VERSION ""

NS_ :

BS_:

BU_: BMS OBC VCU HCM MCU
VAL_TABLE_ Busoff_state 1 "Bus Off" 0 "Normal" ;
VAL_TABLE_ contactor_fault 2 "Open the Way" 1 "Adhesive" 0 "Normal" ;
VAL_TABLE_ LV_power_supply_failure 3 "Sampling Fault" 2 "Overpressure" 1 "Underpressure" 0 "Normal" ;
VAL_TABLE_ HCM_precharge_state 5 "Normal Drive" 4 "Precharge and Locking" 3 "Precharge Fault" 2 "Precharge Completed" 1 "Precharge Process" 0 "Open Circuit" ;
VAL_TABLE_ Charging_wakeup_state 1 "Activation" 0 "Unactivated" ;
VAL_TABLE_ Output_overpressure 1 "Fault" 0 "Normal" ;
VAL_TABLE_ Input_under_pressure 1 "Fault" 0 "Normal" ;
VAL_TABLE_ Input_underpressure 1 "Fault" 0 "Normal" ;
VAL_TABLE_ Enter_overpressure 1 "Fault" 0 "Normal" ;
VAL_TABLE_ Overtemperature_failure 1 "Fault" 0 "Normal" ;
VAL_TABLE_ Self_inspection_fault 1 "Fault" 0 "Normal" ;
VAL_TABLE_ Output_overflow 1 "Fault" 0 "Normal" ;
VAL_TABLE_ Communication_failure 1 "Fault" 0 "Normal" ;
VAL_TABLE_ DCDC_running_state 5 "Fault" 6 "Shutdown" 3 "Enabled" 2 "High Pressure on Top" 1 "Self Pass" 0 "Initialization" ;
VAL_TABLE_ Fault_grade 3 "Severe Grade" 2 "Medium Grades" 1 "Low Micro Classes" 0 "Normal Grade" ;
VAL_TABLE_ OBC_instruct 2 "Enable" 1 "Shutdown" 0 "Reserve" ;
VAL_TABLE_ HCM_hibernation_command 1 "Activation" 0 "Unactivated" ;
VAL_TABLE_ HCM_detection_instruction 1 "Activation" 0 "Unactivated" ;
VAL_TABLE_ contactor_instruction 2 "Closed" 1 "Disconnected" 0 "Reserve" ;
VAL_TABLE_ DCDC_enable 2 "Enabling" 1 "No Power" 0 "Reserve" ;
VAL_TABLE_ St_MCUoffPermit 1 "permit" 0 "not permit" ;
VAL_TABLE_ St_MCUdriverPermit 1 "permit" 0 "not permit" ;
VAL_TABLE_ St_MCU_enable 1 "permint" 0 "not permit" ;
VAL_TABLE_ St_motor 3 "Fault" 2 "Limit Power" 1 "Warning" 0 "reserve" ;
VAL_TABLE_ St_motorMode 3 "slope slip" 2 "speed mode" 1 "torque mode" 0 "stop" ;
VAL_TABLE_ St_motorDirection 3 "reserve" 2 "CW" 1 "CCW" 0 "Stop" ;
VAL_TABLE_ S_motor_direction 3 "Reserve" 2 "CW" 1 "CCW" 0 "N Mode" ;
VAL_TABLE_ S_motor_run_stop 3 "Reserve" 2 "Stop" 1 "Run" 0 "Reserve" ;
VAL_TABLE_ S_motor_control_mode 3 "Reserve" 2 "Speed Mode" 1 "Torque Mode" 0 "Reserve" ;

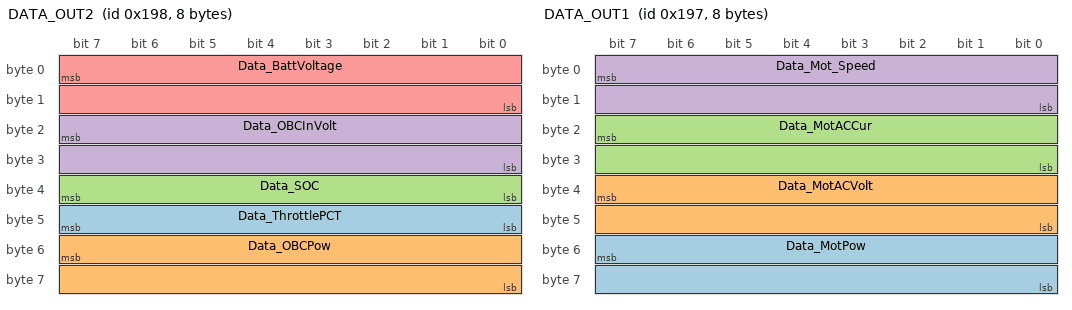
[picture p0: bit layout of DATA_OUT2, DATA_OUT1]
BO_ 408 DATA_OUT2: 8 Vector__XXX
 SG_ Data_ThrottlePCT : 47|8@0+ (1,0) [0|255] "" Vector__XXX
 SG_ Data_OBCPow : 55|16@0+ (1,0) [0|65535] "W" Vector__XXX
 SG_ Data_SOC : 39|8@0+ (1,0) [0|255] "" Vector__XXX
 SG_ Data_OBCInVolt : 23|16@0+ (1,0) [0|65535] "" Vector__XXX
 SG_ Data_BattVoltage : 7|16@0+ (0.1,0) [0|6553.5] "" Vector__XXX

BO_ 407 DATA_OUT1: 8 Vector__XXX
 SG_ Data_MotPow : 55|16@0+ (0.1,0) [0|6553.5] "kW" Vector__XXX
 SG_ Data_MotACVolt : 39|16@0+ (0.1,0) [0|6553.5] "V" Vector__XXX
 SG_ Data_MotACCur : 23|16@0+ (0.1,0) [0|6553.5] "A" Vector__XXX
 SG_ Data_Mot_Speed : 7|16@0+ (1,0) [0|65535] "rpm" Vector__XXX

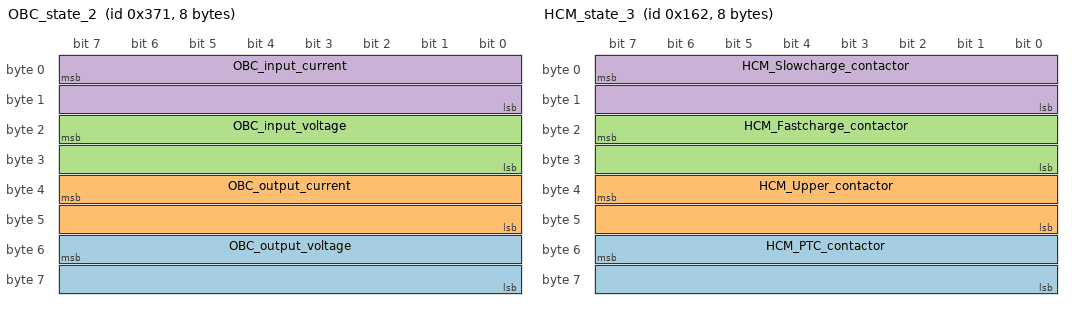
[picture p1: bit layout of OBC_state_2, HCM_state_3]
BO_ 881 OBC_state_2: 8 OBC
 SG_ OBC_output_voltage : 55|16@0+ (0.1,0) [0|6553.5] "V" Vector__XXX
 SG_ OBC_output_current : 39|16@0+ (0.1,-1000) [-1000|5553.5] "A" Vector__XXX
 SG_ OBC_input_voltage : 23|16@0+ (0.1,0) [0|6553.5] "V" Vector__XXX
 SG_ OBC_input_current : 7|16@0+ (0.1,-1000) [-1000|5553.5] "A" Vector__XXX

BO_ 880 OBC_state_1: 8 OBC
 SG_ OBC_Heart_rate : 63|8@0+ (1,0) [0|255] "" Vector__XXX
 SG_ OBC_version_number : 55|8@0+ (0.01,0) [0|255] "" Vector__XXX
 SG_ OBC_temperature : 31|8@0+ (1,-40) [-40|255] "C" Vector__XXX
 SG_ OBC_Overtemperature_failure : 16|1@0+ (1,0) [0|1] "" Vector__XXX
 SG_ OBC_Output_undervoltage : 17|1@0+ (1,0) [0|1] "" Vector__XXX
 SG_ OBC_Output_overvoltage : 18|1@0+ (1,0) [0|1] "" Vector__XXX
 SG_ OBC_Input_undervoltage : 19|1@0+ (1,0) [0|1] "" Vector__XXX
 SG_ OBC_Enter_overvoltage : 20|1@0+ (1,0) [0|1] "" Vector__XXX
 SG_ OBC_hardware_malfunction : 21|1@0+ (1,0) [0|1] "" Vector__XXX
 SG_ OBC_Communication_timeout : 22|1@0+ (1,0) [0|1] "" Vector__XXX
 SG_ OBC_Self_inspection_fault : 23|1@0+ (1,0) [0|1] "" Vector__XXX
 SG_ OBC_PFC_undervoltage : 8|1@0+ (1,0) [0|1] "" Vector__XXX
 SG_ OBC_PFC_overvoltage : 9|1@0+ (1,0) [0|1] "" Vector__XXX
 SG_ OBC_lack_of_phase : 10|1@0+ (1,0) [0|1] "" Vector__XXX
 SG_ OBC_Output_overflow : 11|1@0+ (1,0) [0|1] "" Vector__XXX
 SG_ OBC_running_state : 3|4@0+ (1,0) [0|15] "" Vector__XXX
 SG_ OBC_Fault_grade : 5|2@0+ (1,0) [0|3] "" Vector__XXX

BO_ 355 HCM_state_4: 8 HCM
 SG_ HCM_Busoff_state : 63|8@0+ (1,0) [0|255] "V" Vector__XXX
 SG_ HCM_Battery_voltage : 7|16@0+ (0.1,0) [0|6553.5] "V" Vector__XXX

BO_ 354 HCM_state_3: 8 HCM
 SG_ HCM_PTC_contactor : 55|16@0+ (1,0) [0|6553.5] "V" Vector__XXX
 SG_ HCM_Upper_contactor : 39|16@0+ (0.1,0) [0|6553.5] "V" Vector__XXX
 SG_ HCM_Fastcharge_contactor : 23|16@0+ (0.1,0) [0|6553.5] "V" Vector__XXX
 SG_ HCM_Slowcharge_contactor : 7|16@0+ (0.1,0) [0|6553.5] "V" Vector__XXX

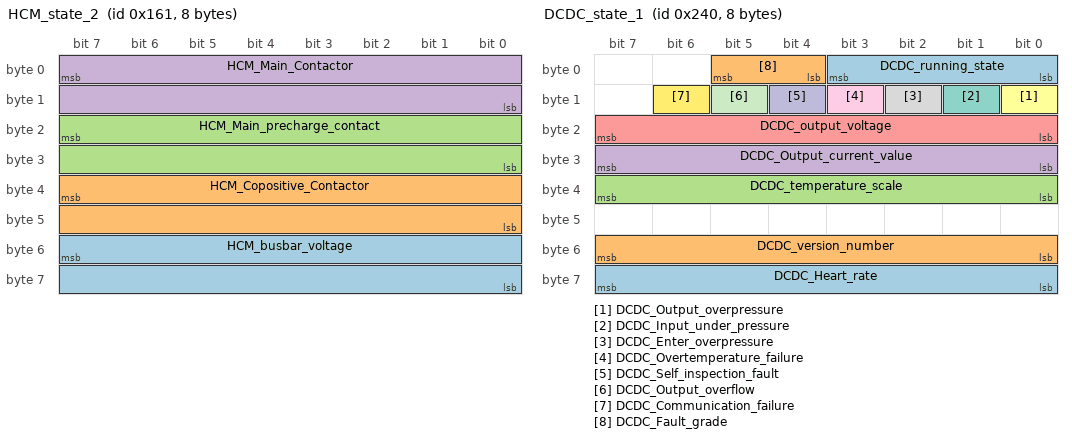
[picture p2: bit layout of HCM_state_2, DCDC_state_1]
BO_ 353 HCM_state_2: 8 HCM
 SG_ HCM_busbar_voltage : 55|16@0+ (0.1,0) [0|6553.5] "V" Vector__XXX
 SG_ HCM_Copositive_Contactor : 39|16@0+ (0.1,0) [0|6553.5] "V" Vector__XXX
 SG_ HCM_Main_precharge_contact : 23|16@0+ (0.1,0) [0|6553.5] "V" Vector__XXX
 SG_ HCM_Main_Contactor : 7|16@0+ (0.1,0) [0|6553.5] "V" Vector__XXX

BO_ 352 HCM_state_1: 8 HCM
 SG_ HCM_Heart_rate : 63|8@0+ (1,0) [0|255] "" Vector__XXX
 SG_ HCM_version_number : 55|8@0+ (0.01,0) [0|255] "" Vector__XXX
 SG_ HCM_Fastcharge_contactor_fault : 33|2@0+ (1,0) [0|3] "" Vector__XXX
 SG_ HCM_Slowcharge_contactor_fault : 35|2@0+ (1,0) [0|3] "" Vector__XXX
 SG_ HCM_Open_cover_fault : 36|1@0+ (1,0) [0|1] "" Vector__XXX
 SG_ HCM_Main_contactor_fault : 25|2@0+ (1,0) [0|3] "" Vector__XXX
 SG_ HCM_Precharge_contactor_fault : 27|2@0+ (1,0) [0|3] "" Vector__XXX
 SG_ HCM_PTC_contactor_fault : 29|2@0+ (1,0) [0|3] "" Vector__XXX
 SG_ HCM_AC_contactor_fault : 31|2@0+ (1,0) [0|3] "" Vector__XXX
 SG_ HCM_Slowcharge_contactor_status : 16|1@0+ (1,0) [0|1] "" Vector__XXX
 SG_ HCM_Quickcharge_contactor_status : 17|1@0+ (1,0) [0|1] "" Vector__XXX
 SG_ HCM_Self_inspection_fault : 18|1@0+ (1,0) [0|1] "" Vector__XXX
 SG_ HCM_HV_interlock_fault : 19|1@0+ (1,0) [0|1] "" Vector__XXX
 SG_ HCM_LV_power_supply_failure : 21|2@0+ (1,0) [0|3] "" Vector__XXX
 SG_ HCM_VCU_communication_failure : 22|1@0+ (1,0) [0|1] "" Vector__XXX
 SG_ HCM_BMS_communication_failure : 23|1@0+ (1,0) [0|1] "" Vector__XXX
 SG_ HCM_precharge_state : 11|4@0+ (1,0) [0|15] "" Vector__XXX
 SG_ HCM_Main_Contactor_Status : 12|1@0+ (1,0) [0|1] "" Vector__XXX
 SG_ HCM_Precharge_contactor_status : 13|1@0+ (1,0) [0|1] "" Vector__XXX
 SG_ HCM_PTC_contactor_status : 14|1@0+ (1,0) [0|1] "" Vector__XXX
 SG_ HCM_Air_conditioning : 15|1@0+ (1,0) [0|1] "" Vector__XXX
 SG_ HCM_running_state : 3|4@0+ (1,0) [0|15] "" Vector__XXX
 SG_ HCM_Fault_grade : 5|2@0+ (1,0) [0|3] "" Vector__XXX
 SG_ HCM_ON_file_status : 6|1@0+ (1,0) [0|1] "" Vector__XXX
 SG_ HCM_Charging_wakeup_state : 7|1@0+ (1,0) [0|1] "" Vector__XXX

BO_ 576 DCDC_state_1: 8 Vector__XXX
 SG_ DCDC_Heart_rate : 63|8@0+ (1,0) [0|255] "" Vector__XXX
 SG_ DCDC_version_number : 55|8@0+ (0.01,0) [0|255] "" Vector__XXX
 SG_ DCDC_temperature_scale : 39|8@0+ (1,-40) [-40|215] "C" Vector__XXX
 SG_ DCDC_Output_current_value : 31|8@0+ (1,0) [0|255] "A" Vector__XXX
 SG_ DCDC_output_voltage : 23|8@0+ (0.1,0) [0|255] "V" Vector__XXX
 SG_ DCDC_Output_overpressure : 8|1@0+ (1,0) [0|1] "" Vector__XXX
 SG_ DCDC_Input_under_pressure : 9|1@0+ (1,0) [0|1] "" Vector__XXX
 SG_ DCDC_Enter_overpressure : 10|1@0+ (1,0) [0|1] "" Vector__XXX
 SG_ DCDC_Overtemperature_failure : 11|1@0+ (1,0) [0|1] "" Vector__XXX
 SG_ DCDC_Self_inspection_fault : 12|1@0+ (1,0) [0|1] "" Vector__XXX
 SG_ DCDC_Output_overflow : 13|1@0+ (1,0) [0|1] "" Vector__XXX
 SG_ DCDC_Communication_failure : 14|1@0+ (1,0) [0|1] "" Vector__XXX
 SG_ DCDC_running_state : 3|4@0+ (1,0) [0|15] "" Vector__XXX
 SG_ DCDC_Fault_grade : 5|2@0+ (1,0) [0|3] "" Vector__XXX

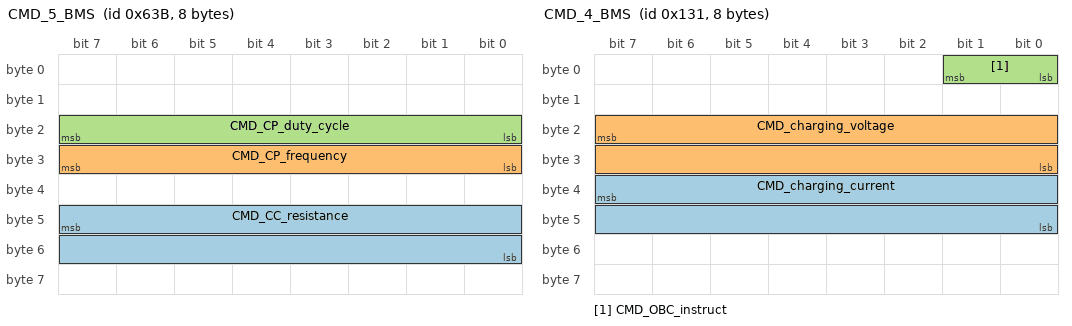
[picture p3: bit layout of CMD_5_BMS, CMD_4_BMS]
BO_ 1595 CMD_5_BMS: 8 BMS
 SG_ CMD_CC_resistance : 47|16@0+ (1,0) [0|65535] "" Vector__XXX
 SG_ CMD_CP_frequency : 31|8@0+ (10,0) [0|255] "" Vector__XXX
 SG_ CMD_CP_duty_cycle : 23|8@0+ (1,0) [0|255] "" Vector__XXX

BO_ 305 CMD_4_BMS: 8 BMS
 SG_ CMD_charging_current : 39|16@0+ (0.1,-1000) [-1000|5553.5] "A" Vector__XXX
 SG_ CMD_charging_voltage : 23|16@0+ (0.1,0) [0|6553.5] "V" Vector__XXX
 SG_ CMD_OBC_instruct : 1|2@0+ (1,0) [0|3] "" Vector__XXX

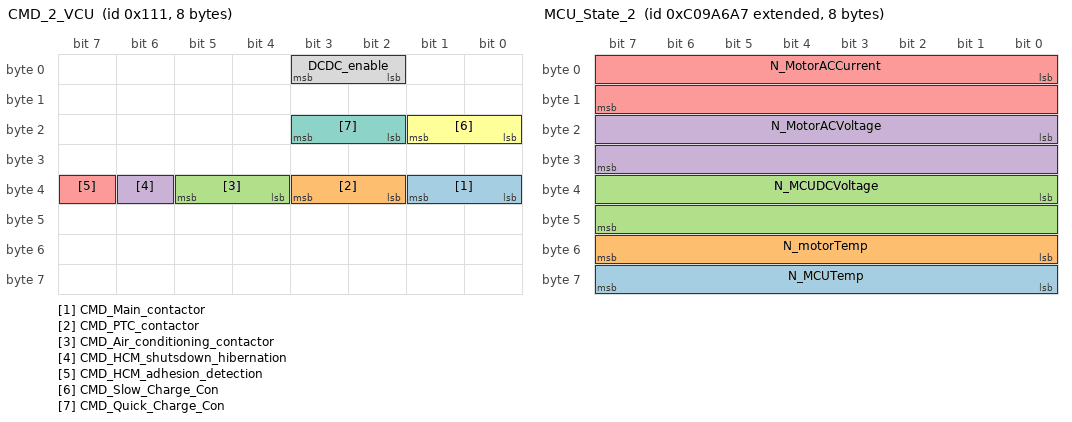
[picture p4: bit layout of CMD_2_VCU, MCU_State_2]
BO_ 273 CMD_2_VCU: 8 VCU
 SG_ CMD_Main_contactor : 33|2@0+ (1,0) [0|3] "" Vector__XXX
 SG_ CMD_PTC_contactor : 35|2@0+ (1,0) [0|0] "" Vector__XXX
 SG_ CMD_Air_conditioning_contactor : 37|2@0+ (1,0) [0|3] "" Vector__XXX
 SG_ CMD_HCM_shutsdown_hibernation : 38|1@0+ (1,0) [0|1] "" Vector__XXX
 SG_ CMD_HCM_adhesion_detection : 39|1@0+ (1,0) [0|1] "" Vector__XXX
 SG_ CMD_Slow_Charge_Con : 17|2@0+ (1,0) [0|3] "" Vector__XXX
 SG_ CMD_Quick_Charge_Con : 19|2@0+ (1,0) [0|3] "" Vector__XXX
 SG_ DCDC_enable : 3|2@0+ (1,0) [0|3] "" Vector__XXX

BO_ 272 CMD_1_VCU: 8 VCU
 SG_ CMD_Heart_rate : 63|8@0+ (1,0) [0|255] "" Vector__XXX

BO_ 2349508263 MCU_Faliure_1: 8 VCU
 SG_ MCU_Number : 56|8@1+ (1,0) [0|255] "" Vector__XXX
 SG_ Motor_Num : 52|4@1+ (1,0) [0|15] "" Vector__XXX
 SG_ Motor_Quantity : 48|4@1+ (1,0) [0|15] "" Vector__XXX
 SG_ Encoder_failure : 20|1@1+ (1,0) [0|1] "" Vector__XXX
 SG_ CAN_offline_failure : 19|1@1+ (1,0) [0|1] "" Vector__XXX
 SG_ Motor_over_temperature_fault : 18|1@1+ (1,0) [0|1] "" Vector__XXX
 SG_ Motor_over_temperature_warning : 17|1@1+ (1,0) [0|1] "" Vector__XXX
 SG_ Reserved : 16|1@1+ (1,0) [0|1] "" Vector__XXX
 SG_ Overspeed_fault : 15|1@1+ (1,0) [0|1] "" Vector__XXX
 SG_ Module_over_temperature_warning : 14|1@1+ (1,0) [0|1] "" Vector__XXX
 SG_ Module_over_temperature_fault : 13|1@1+ (1,0) [0|1] "" Vector__XXX
 SG_ Busbar_undervoltage_fault : 12|1@1+ (1,0) [0|1] "" Vector__XXX
 SG_ Bus_overvoltage_fault : 11|1@1+ (1,0) [0|1] "" Vector__XXX
 SG_ Total_hardware_failure : 10|1@1+ (1,0) [0|1] "" Vector__XXX
 SG_ Hardware_overvoltage_fault : 9|1@1+ (1,0) [0|1] "" Vector__XXX
 SG_ Software_overcurrent_fault : 8|1@1+ (1,0) [0|1] "" Vector__XXX
 SG_ Low_voltage_undervoltage_fault : 7|1@1+ (1,0) [0|1] "" Vector__XXX
 SG_ Stall_failure : 6|1@1+ (1,0) [0|1] "" Vector__XXX
 SG_ AC_Hall_failure : 5|1@1+ (1,0) [0|1] "" Vector__XXX
 SG_ Temperature_difference_failure : 4|1@1+ (1,0) [0|1] "" Vector__XXX
 SG_ Fan_failure : 3|1@1+ (1,0) [0|1] "" Vector__XXX
 SG_ Zero_offset_fault : 2|1@1+ (1,0) [0|1] "" Vector__XXX
 SG_ Hardware_overcurrent_fault : 1|1@1+ (1,0) [0|1] "" Vector__XXX
 SG_ Hardware_driver_failure : 0|1@1+ (1,0) [0|1] "" Vector__XXX

BO_ 2349442727 MCU_State_2: 8 VCU
 SG_ N_MCUTemp : 56|8@1+ (1,-40) [-40|150] "C" Vector__XXX
 SG_ N_motorTemp : 48|8@1+ (1,-40) [-40|150] "C" Vector__XXX
 SG_ N_MCUDCVoltage : 32|16@1+ (0.1,0) [0|800] "V" Vector__XXX
 SG_ N_MotorACVoltage : 16|16@1+ (0.1,0) [0|800] "V" Vector__XXX
 SG_ N_MotorACCurrent : 0|16@1+ (0.1,0) [0|800] "A" Vector__XXX

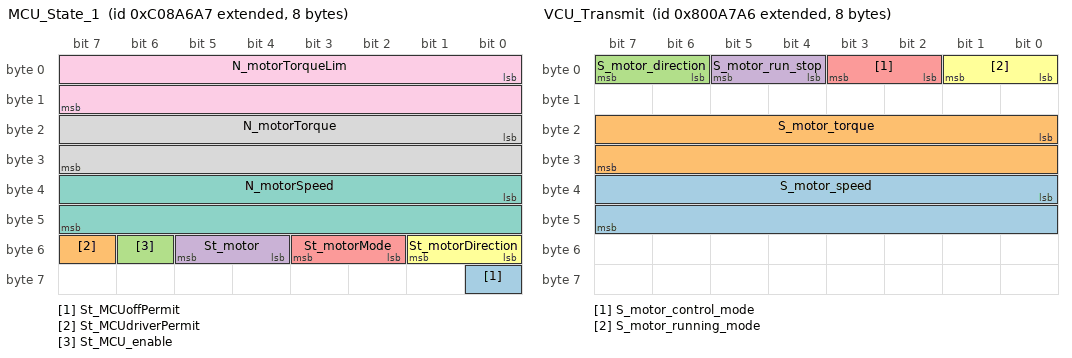
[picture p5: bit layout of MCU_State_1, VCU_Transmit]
BO_ 2349377191 MCU_State_1: 8 VCU
 SG_ St_MCUoffPermit : 56|1@1+ (1,0) [0|1] "" Vector__XXX
 SG_ St_MCUdriverPermit : 55|1@1+ (1,0) [0|1] "" Vector__XXX
 SG_ St_MCU_enable : 54|1@1+ (1,0) [0|3] "" Vector__XXX
 SG_ St_motor : 52|2@1+ (1,0) [0|3] "" Vector__XXX
 SG_ St_motorMode : 50|2@1+ (1,0) [0|3] "" Vector__XXX
 SG_ St_motorDirection : 48|2@1+ (1,0) [0|3] "" Vector__XXX
 SG_ N_motorSpeed : 32|16@1+ (1,-15000) [-15000|15000] "rpm" Vector__XXX
 SG_ N_motorTorque : 16|16@1+ (1,-15000) [-15000|15000] "Nm" Vector__XXX
 SG_ N_motorTorqueLim : 0|16@1+ (1,-15000) [-15000|15000] "Nm" Vector__XXX

BO_ 2281744294 VCU_Transmit: 8 MCU
 SG_ S_motor_speed : 32|16@1- (1,-15000) [-15000|15000] "rpm" Vector__XXX
 SG_ S_motor_torque : 16|16@1- (1,-15000) [-15000|15000] "Nm" Vector__XXX
 SG_ S_motor_direction : 6|2@1+ (1,0) [0|3] "" Vector__XXX
 SG_ S_motor_run_stop : 4|2@1+ (1,0) [0|3] "" Vector__XXX
 SG_ S_motor_control_mode : 2|2@1+ (1,0) [0|3] "" Vector__XXX
 SG_ S_motor_running_mode : 0|2@1+ (1,0) [0|0] "" Vector__XXX

BA_DEF_ BO_  "GenMsgCycleTime" INT 0 0;
BA_DEF_DEF_  "GenMsgCycleTime" 0;
BA_ "GenMsgCycleTime" BO_ 881 100;
BA_ "GenMsgCycleTime" BO_ 880 100;
BA_ "GenMsgCycleTime" BO_ 355 20;
BA_ "GenMsgCycleTime" BO_ 354 20;
BA_ "GenMsgCycleTime" BO_ 353 20;
BA_ "GenMsgCycleTime" BO_ 352 100;
BA_ "GenMsgCycleTime" BO_ 576 100;
BA_ "GenMsgCycleTime" BO_ 1595 100;
BA_ "GenMsgCycleTime" BO_ 305 50;
BA_ "GenMsgCycleTime" BO_ 273 50;
BA_ "GenMsgCycleTime" BO_ 272 20;
BA_ "GenMsgCycleTime" BO_ 2349508263 100;
BA_ "GenMsgCycleTime" BO_ 2349442727 100;
BA_ "GenMsgCycleTime" BO_ 2349377191 10;
BA_ "GenMsgCycleTime" BO_ 2281744294 10;
VAL_ 880 OBC_Overtemperature_failure 1 "Fault" 0 "Normal" ;
VAL_ 880 OBC_Output_undervoltage 1 "Fault" 0 "Normal" ;
VAL_ 880 OBC_Output_overvoltage 1 "Fault" 0 "Normal" ;
VAL_ 880 OBC_Input_undervoltage 1 "Fault" 0 "Normal" ;
VAL_ 880 OBC_Enter_overvoltage 1 "Fault" 0 "Normal" ;
VAL_ 880 OBC_hardware_malfunction 1 "Fault" 0 "Normal" ;
VAL_ 880 OBC_Communication_timeout 1 "Fault" 0 "Normal" ;
VAL_ 880 OBC_Self_inspection_fault 1 "Fault" 0 "Normal" ;
VAL_ 880 OBC_PFC_undervoltage 1 "Fault" 0 "Normal" ;
VAL_ 880 OBC_PFC_overvoltage 1 "Fault" 0 "Normal" ;
VAL_ 880 OBC_lack_of_phase 1 "Fault" 0 "Normal" ;
VAL_ 880 OBC_Output_overflow 1 "Fault" 0 "Normal" ;
VAL_ 880 OBC_running_state 5 "Fault" 6 "Shutdown" 3 "Enabled" 2 "High Pressure on Top" 1 "Self Pass" 0 "Initialization" ;
VAL_ 880 OBC_Fault_grade 3 "Severe Grade" 2 "Medium Grades" 1 "Low Micro Classes" 0 "Normal Grade" ;
VAL_ 355 HCM_Busoff_state 1 "Bus Off" 0 "Normal" ;
VAL_ 352 HCM_Fastcharge_contactor_fault 2 "Open the Way" 1 "Adhesive" 0 "Normal" ;
VAL_ 352 HCM_Slowcharge_contactor_fault 2 "Open the Way" 1 "Adhesive" 0 "Normal" ;
VAL_ 352 HCM_Open_cover_fault 1 "Fault" 0 "Normal" ;
VAL_ 352 HCM_Main_contactor_fault 2 "Open the Way" 1 "Adhesive" 0 "Normal" ;
VAL_ 352 HCM_Precharge_contactor_fault 2 "Open the Way" 1 "Adhesive" 0 "Normal" ;
VAL_ 352 HCM_PTC_contactor_fault 2 "Open the Way" 1 "Adhesive" 0 "Normal" ;
VAL_ 352 HCM_AC_contactor_fault 2 "Open the Way" 1 "Adhesive" 0 "Normal" ;
VAL_ 352 HCM_Slowcharge_contactor_status 2 "Closed" 1 "Disconnected" 0 "Reserve" ;
VAL_ 352 HCM_Quickcharge_contactor_status 2 "Closed" 1 "Disconnected" 0 "Reserve" ;
VAL_ 352 HCM_Self_inspection_fault 1 "Fault" 0 "Normal" ;
VAL_ 352 HCM_HV_interlock_fault 1 "Fault" 0 "Normal" ;
VAL_ 352 HCM_LV_power_supply_failure 3 "Sampling Fault" 2 "Overpressure" 1 "Underpressure" 0 "Normal" ;
VAL_ 352 HCM_VCU_communication_failure 1 "Fault" 0 "Normal" ;
VAL_ 352 HCM_BMS_communication_failure 1 "Fault" 0 "Normal" ;
VAL_ 352 HCM_precharge_state 5 "Normal Drive" 4 "Precharge and Locking" 3 "Precharge Fault" 2 "Precharge Completed" 1 "Precharge Process" 0 "Open Circuit" ;
VAL_ 352 HCM_Main_Contactor_Status 2 "Closed" 1 "Disconnected" 0 "Reserve" ;
VAL_ 352 HCM_Precharge_contactor_status 2 "Closed" 1 "Disconnected" 0 "Reserve" ;
VAL_ 352 HCM_PTC_contactor_status 2 "Closed" 1 "Disconnected" 0 "Reserve" ;
VAL_ 352 HCM_Air_conditioning 2 "Closed" 1 "Disconnected" 0 "Reserve" ;
VAL_ 352 HCM_running_state 5 "Fault" 6 "Shutdown" 3 "Enabled" 2 "High Pressure on Top" 1 "Self Pass" 0 "Initialization" ;
VAL_ 352 HCM_Fault_grade 3 "Severe Grade" 2 "Medium Grades" 1 "Low Micro Classes" 0 "Normal Grade" ;
VAL_ 352 HCM_ON_file_status 1 "Activation" 0 "Unactivated" ;
VAL_ 352 HCM_Charging_wakeup_state 1 "Activation" 0 "Unactivated" ;
VAL_ 576 DCDC_Output_overpressure 1 "Fault" 0 "Normal" ;
VAL_ 576 DCDC_Input_under_pressure 1 "Fault" 0 "Normal" ;
VAL_ 576 DCDC_Enter_overpressure 1 "Fault" 0 "Normal" ;
VAL_ 576 DCDC_Overtemperature_failure 1 "Fault" 0 "Normal" ;
VAL_ 576 DCDC_Self_inspection_fault 1 "Fault" 0 "Normal" ;
VAL_ 576 DCDC_Output_overflow 1 "Fault" 0 "Normal" ;
VAL_ 576 DCDC_Communication_failure 1 "Fault" 0 "Normal" ;
VAL_ 576 DCDC_running_state 5 "Fault" 6 "Shutdown" 3 "Enabled" 2 "High Pressure on Top" 1 "Self Pass" 0 "Initialization" ;
VAL_ 576 DCDC_Fault_grade 3 "Severe Grade" 2 "Medium Grades" 1 "Low Micro Classes" 0 "Normal Grade" ;
VAL_ 305 CMD_OBC_instruct 2 "Enable" 1 "Shutdown" 0 "Reserve" ;
VAL_ 273 CMD_Main_contactor 2 "Closed" 1 "Disconnected" 0 "Reserve" ;
VAL_ 273 CMD_PTC_contactor 2 "Closed" 1 "Disconnected" 0 "Reserve" ;
VAL_ 273 CMD_Air_conditioning_contactor 2 "Closed" 1 "Disconnected" 0 "Reserve" ;
VAL_ 273 CMD_HCM_shutsdown_hibernation 1 "Activation" 0 "Unactivated" ;
VAL_ 273 CMD_HCM_adhesion_detection 1 "Activation" 0 "Unactivated" ;
VAL_ 273 CMD_Slow_Charge_Con 2 "Closed" 1 "Disconnected" 0 "Reserve" ;
VAL_ 273 CMD_Quick_Charge_Con 2 "Closed" 1 "Disconnected" 0 "Reserve" ;
VAL_ 273 DCDC_enable 2 "Enabling" 1 "No Power" 0 "Reserve" ;
VAL_ 2349377191 St_MCUoffPermit 1 "permit" 0 "not permit" ;
VAL_ 2349377191 St_MCUdriverPermit 1 "permit" 0 "not permit" ;
VAL_ 2349377191 St_MCU_enable 1 "permint" 0 "not permit" ;
VAL_ 2349377191 St_motor 3 "Fault" 2 "Limit Power" 1 "Warning" 0 "reserve" ;
VAL_ 2349377191 St_motorMode 3 "slope slip" 2 "speed mode" 1 "torque mode" 0 "stop" ;
VAL_ 2349377191 St_motorDirection 3 "reserve" 2 "CW" 1 "CCW" 0 "Stop" ;
VAL_ 2281744294 S_motor_direction 3 "Reserve" 2 "CW" 1 "CCW" 0 "N Mode" ;
VAL_ 2281744294 S_motor_run_stop 3 "Reserve" 2 "Stop" 1 "Run" 0 "Reserve" ;
VAL_ 2281744294 S_motor_control_mode 3 "Reserve" 2 "Speed Mode" 1 "Torque Mode" 0 "Reserve" ;
